# STC32G144K246 register map
Vendor: STC; File version: 2.0
Registers are 8-bit, read-write, no defined reset value unless marked. A register's access mark holds for its fields unless they carry their own. Offsets are from the block's base; [hi:lo] are bit positions.

## UART7 — USART7 收发、运行模式与超时
Base 0x007EF7A0
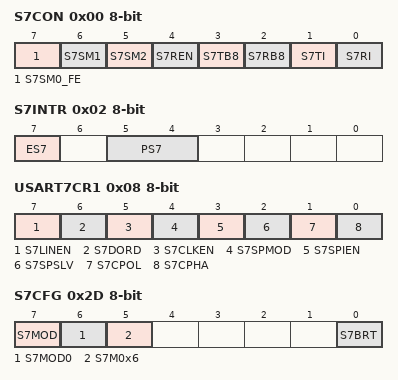
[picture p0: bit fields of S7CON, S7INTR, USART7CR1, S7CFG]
0x00 S7CON — 串口7控制寄存器
  [7] S7SM0_FE — 当S7CFG寄存器中的S7MOD0位为1时，该位为帧错误检测标志位。当串口7在接收过程中检
  [6] S7SM1 — 尚未自动匹配到此字段的独立说明；请查看下方章节说明。
  [5] S7SM2 — 允许模式2 或模式3 多机通信控制位。当串口7 使用模式2 或模式3 时，如果S7SM2 位为1 且 S7REN 位为1，则接收机处于地址帧筛选状态。此时可以利用接收到的第9 位（即S7RB8）来筛 选地址帧，若S7RB8=1，说明该帧是地址帧，地址信息可以进入S7BUF，并使S7RI 为1，进而
  [4] S7REN — 允许/禁止串口接收控制位
    0=禁止串口接收数据; 1=允许串口接收数据
  [3] S7TB8 — 当串口7 使用模式2 或模式3 时，S7TB8 为要发送的第9 位数据，按需要由软件置位或清0。 在模式0 和模式1 中，该位不用。
  [2] S7RB8 — 当串口7 使用模式2 或模式3 时，S7RB8 为接收到的第9 位数据，一般用作校验位或者地址帧 /数据帧标志位。在模式0 和模式1 中，该位不用。
  [1] S7TI — 串口7发送完成中断请求标志。需要软件清零。
  [0] S7RI — 串口7接收完成中断请求标志。需要软件清零。
0x02 S7INTR — 串口7中断寄存器
  [7] ES7 — 串口7 中断使能控制位
    0=禁止串口7 中断; 1=允许串口7 中断
  [5:4] PS7 — 串口7 中断优先级控制位
    0=串口7 中断优先级为0 级（最低级）; 1=串口7 中断优先级为1 级（较低级）; 2=串口7 中断优先级为2 级（较高级）; 3=串口7 中断优先级为3 级（最高级）
0x05 UR7TOSR ro — 串口7接收超时状态寄存器
  [0] UR7TOIF — 串口7 超时中断请求标志位。标志位需要软件向UR7CTOIF 位写“1”清零
0x08 USART7CR1 — 串口7控制寄存器1
  [7] S7LINEN — LIN 模式使能位
    0=禁止LIN 模式; 1=使能LIN 模式
  [6] S7DORD — SPI 模式数据位发送/接收的顺序
    0=先发送/接收数据的高位（MSB）; 1=先发送/接收数据的低位（LSB）
  [5] S7CLKEN — SmartCard 模式时钟输出控制位
    0=禁止时钟输出; 1=使能时钟输出
  [4] S7SPMOD — SPI 模式使能位
    0=禁止SPI 模式; 1=使能SPI 模式
  [3] S7SPIEN — SPI 使能位
    0=禁止SPI 功能; 1=使能SPI 功能
  [2] S7SPSLV — SPI 从机模式使能位
    0=SPI 为主机模式; 1=SPI 为从机模式
  [1] S7CPOL — SPI 时钟极性控制
    0=SCLK 空闲时为低电平，SCLK 的前时钟沿为上升沿，后时钟沿为下降沿; 1=SCLK 空闲时为高电平，SCLK 的前时钟沿为下降沿，后时钟沿为上升沿
  [0] S7CPHA — SPI 时钟相位控制
    0=数据SS 管脚为低电平驱动第一位数据并在SCLK 的后时钟沿改变数据，前时钟沿采样数据; 1=数据在SCLK 的前时钟沿驱动，后时钟沿采样
0x2D S7CFG — 串口7配置寄存器
  [7] S7MOD — 串口7 波特率控制位
    0=SYSclk波特率=𝟔𝟒; 1=SYSclk波特率=𝟑𝟐
  [6] S7MOD0 — 帧错误检测控制位
    0=无帧错检测功能; 1=使能帧错误检测功能。此时S7CON 的S7SM0/FE 为FE 功能，即为帧错误检测标志位。
  [5] S7M0x6 — 串口7 模式0 的通讯速度控制
    0=串口7 模式0 的波特率不加倍，固定为Fosc/12; 1=串口7 模式0 的波特率6 倍速，即固定为Fosc/12*6 ＝ Fosc/2
  [0] S7BRT — 串口7 波特率发生器选择位
    0=选择定时器2 作为波特率发生器（默认值）; 1=选择定时器7 作为波特率发生器

## UART8 — USART8 收发、运行模式与超时
Base 0x007EF7D0
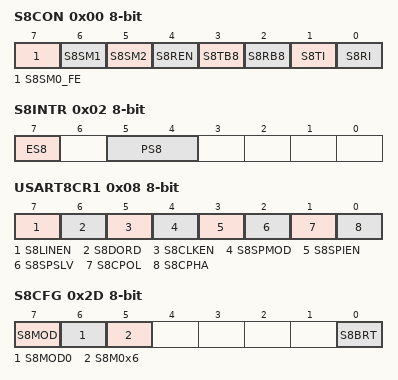
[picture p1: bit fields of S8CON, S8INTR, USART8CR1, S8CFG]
0x00 S8CON — 串口8控制寄存器
  [7] S8SM0_FE — 当S8CFG寄存器中的S8MOD0位为1时，该位为帧错误检测标志位。当串口8在接收过程中检
  [6] S8SM1 — 尚未自动匹配到此字段的独立说明；请查看下方章节说明。
  [5] S8SM2 — 允许模式2 或模式3 多机通信控制位。当串口8 使用模式2 或模式3 时，如果S8SM2 位为1 且 S8REN 位为1，则接收机处于地址帧筛选状态。此时可以利用接收到的第9 位（即S8RB8）来筛 选地址帧，若S8RB8=1，说明该帧是地址帧，地址信息可以进入S8BUF，并使S8RI 为1，进而
  [4] S8REN — 允许/禁止串口接收控制位
    0=禁止串口接收数据; 1=允许串口接收数据
  [3] S8TB8 — 当串口8 使用模式2 或模式3 时，S8TB8 为要发送的第9 位数据，按需要由软件置位或清0。 在模式0 和模式1 中，该位不用。
  [2] S8RB8 — 当串口8 使用模式2 或模式3 时，S8RB8 为接收到的第9 位数据，一般用作校验位或者地址帧 /数据帧标志位。在模式0 和模式1 中，该位不用。
  [1] S8TI — 串口8发送完成中断请求标志。需要软件清零。
  [0] S8RI — 串口8接收完成中断请求标志。需要软件清零。
0x02 S8INTR — 串口8中断寄存器
  [7] ES8 — 串口8 中断使能控制位
    0=禁止串口8 中断; 1=允许串口8 中断
  [5:4] PS8 — 串口8 中断优先级控制位
    0=串口8 中断优先级为0 级（最低级）; 1=串口8 中断优先级为1 级（较低级）; 2=串口8 中断优先级为2 级（较高级）; 3=串口8 中断优先级为3 级（最高级）
0x05 UR8TOSR ro — 串口8接收超时状态寄存器
  [0] UR8TOIF — 串口8 超时中断请求标志位。标志位需要软件向UR8CTOIF 位写“1”清零
0x08 USART8CR1 — 串口8控制寄存器1
  [7] S8LINEN — LIN 模式使能位
    0=禁止LIN 模式; 1=使能LIN 模式
  [6] S8DORD — SPI 模式数据位发送/接收的顺序
    0=先发送/接收数据的高位（MSB）; 1=先发送/接收数据的低位（LSB）
  [5] S8CLKEN — SmartCard 模式时钟输出控制位
    0=禁止时钟输出; 1=使能时钟输出
  [4] S8SPMOD — SPI 模式使能位
    0=禁止SPI 模式; 1=使能SPI 模式
  [3] S8SPIEN — SPI 使能位
    0=禁止SPI 功能; 1=使能SPI 功能
  [2] S8SPSLV — SPI 从机模式使能位
    0=SPI 为主机模式; 1=SPI 为从机模式
  [1] S8CPOL — SPI 时钟极性控制
    0=SCLK 空闲时为低电平，SCLK 的前时钟沿为上升沿，后时钟沿为下降沿; 1=SCLK 空闲时为高电平，SCLK 的前时钟沿为下降沿，后时钟沿为上升沿
  [0] S8CPHA — SPI 时钟相位控制
    0=数据SS 管脚为低电平驱动第一位数据并在SCLK 的后时钟沿改变数据，前时钟沿采样数据; 1=数据在SCLK 的前时钟沿驱动，后时钟沿采样
0x2D S8CFG — 串口8配置寄存器
  [7] S8MOD — 串口8 波特率控制位
    0=SYSclk波特率=𝟔𝟒; 1=SYSclk波特率=𝟑𝟐
  [6] S8MOD0 — 帧错误检测控制位
    0=无帧错检测功能; 1=使能帧错误检测功能。此时S8CON 的S8SM0/FE 为FE 功能，即为帧错误检测标志位。
  [5] S8M0x6 — 串口8 模式0 的通讯速度控制
    0=串口8 模式0 的波特率不加倍，固定为Fosc/12; 1=串口8 模式0 的波特率6 倍速，即固定为Fosc/12*6 ＝ Fosc/2
  [0] S8BRT — 串口8 波特率发生器选择位
    0=选择定时器2 作为波特率发生器（默认值）; 1=选择定时器8 作为波特率发生器
